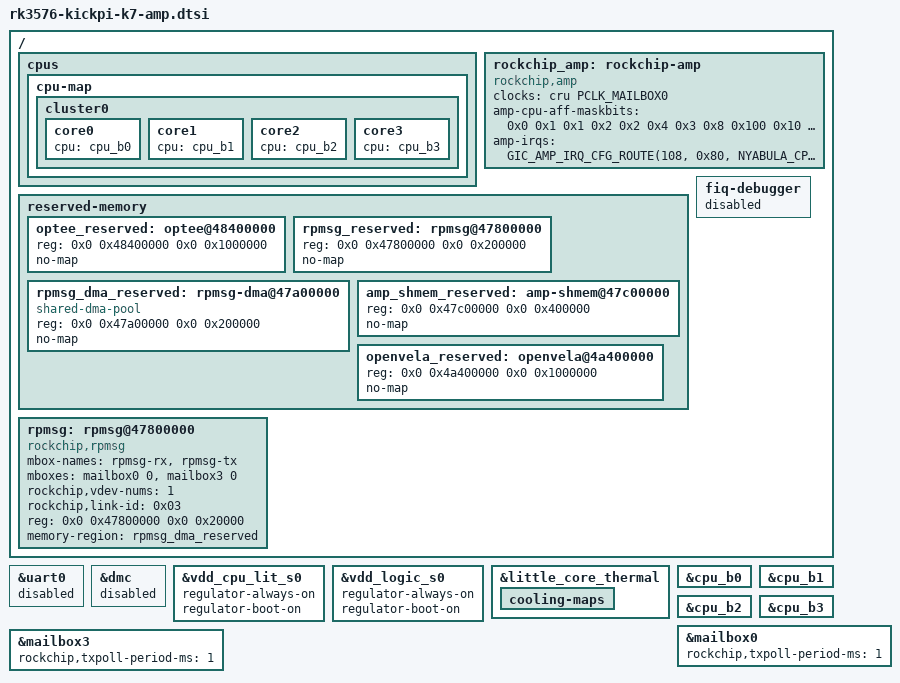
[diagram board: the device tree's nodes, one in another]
// SPDX-License-Identifier: (GPL-2.0+ OR MIT)
/*
 * KICKPI-K7 Linux side of the Nyabula four-A53/four-A72 AMP deployment.
 *
 * Include this file after the normal board DTS.  N-Boot loads the openvela
 * image at 0x4a400000 on CPU0; Linux starts on CPU0x100 and owns only A72s.
 * Mailbox routing below is still the legacy transport contract; this file
 * is not a board-release configuration until transport/GIC migration passes.
 */

#include <dt-bindings/soc/rockchip-amp.h>

#define NYABULA_CPU_AFFINITY(cpu, cluster) (((cpu) << 0) | ((cluster) << 8))

/delete-node/ &cpu_l0;
/delete-node/ &cpu_l1;
/delete-node/ &cpu_l2;
/delete-node/ &cpu_l3;
/delete-node/ &pmu_a53;
/delete-node/ &{/cpus/cpu-map};

/ {
	cpus {
		cpu-map {
			cluster0 {
				core0 { cpu = <&cpu_b0>; };
				core1 { cpu = <&cpu_b1>; };
				core2 { cpu = <&cpu_b2>; };
				core3 { cpu = <&cpu_b3>; };
			};
		};
	};

	rockchip_amp: rockchip-amp {
		compatible = "rockchip,amp";
		clocks = <&cru PCLK_MAILBOX0>;

		amp-cpu-aff-maskbits = /bits/ 64 <
			0x0 0x1 0x1 0x2 0x2 0x4 0x3 0x8
			0x100 0x10 0x101 0x20 0x102 0x40 0x103 0x80>;
		amp-irqs = /bits/ 64 <
			GIC_AMP_IRQ_CFG_ROUTE(108, 0x80,
				NYABULA_CPU_AFFINITY(0, 0))
			GIC_AMP_IRQ_CFG_ROUTE(174, 0x80,
				NYABULA_CPU_AFFINITY(0, 0))>;
		status = "okay";
	};

	reserved-memory {
		#address-cells = <2>;
		#size-cells = <2>;
		ranges;

		/* BL32: 2 MiB TEE OS, 12 MiB TA RAM and 2 MiB shared RAM. */
		optee_reserved: optee@48400000 {
			reg = <0x0 0x48400000 0x0 0x1000000>;
			no-map;
		};

		rpmsg_reserved: rpmsg@47800000 {
			reg = <0x0 0x47800000 0x0 0x200000>;
			no-map;
		};

		rpmsg_dma_reserved: rpmsg-dma@47a00000 {
			compatible = "shared-dma-pool";
			reg = <0x0 0x47a00000 0x0 0x200000>;
			no-map;
		};

		amp_shmem_reserved: amp-shmem@47c00000 {
			reg = <0x0 0x47c00000 0x0 0x400000>;
			no-map;
		};

		openvela_reserved: openvela@4a400000 {
			reg = <0x0 0x4a400000 0x0 0x1000000>;
			no-map;
		};
	};

	rpmsg: rpmsg@47800000 {
		compatible = "rockchip,rpmsg";
		mbox-names = "rpmsg-rx", "rpmsg-tx";
		mboxes = <&mailbox0 0 &mailbox3 0>;
		rockchip,vdev-nums = <1>;
		rockchip,link-id = <0x03>;
		reg = <0x0 0x47800000 0x0 0x20000>;
		memory-region = <&rpmsg_dma_reserved>;
		status = "okay";
	};

	fiq-debugger {
		status = "disabled";
	};
};

&uart0 {
	status = "disabled";
};

&dmc {
	status = "disabled";
};

&vdd_cpu_lit_s0 {
	/delete-property/ regulator-init-microvolt;
	regulator-always-on;
	regulator-boot-on;
	/delete-node/ regulator-state-mem;
};

&vdd_logic_s0 {
	/delete-property/ regulator-init-microvolt;
	regulator-always-on;
	regulator-boot-on;
	/delete-node/ regulator-state-mem;
};

&little_core_thermal {
	cooling-maps {
		/delete-node/ map0;
	};
};

&cpu_b0 {
	status = "okay";
};

&cpu_b1 {
	status = "okay";
};

&cpu_b2 {
	status = "okay";
};

&cpu_b3 {
	status = "okay";
};

&mailbox0 {
	rockchip,txpoll-period-ms = <1>;
	status = "okay";
};

&mailbox3 {
	rockchip,txpoll-period-ms = <1>;
	status = "okay";
};
